# STMP3770 register map
Vendor: Freescale Semiconductor (NXP); Series: STMP37xx; File version: 1.0
CPU: other r0p0, little endian, no MPU, no FPU, 2 interrupt priority bits
Registers are 32-bit, read-write, reset 0x0 unless marked. A register's access mark holds for its fields unless they carry their own. Offsets are from the block's base; [hi:lo] are bit positions; <NAME> marks a mode.

## AUDIOOUT — 音频 DAC 输出(耳机/线路输出的音量、滤波与 DMA 控制)
Base 0x80048000
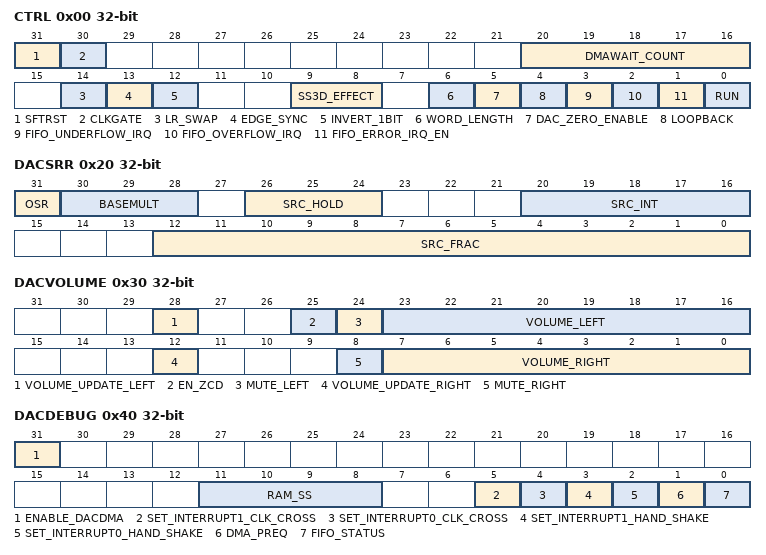
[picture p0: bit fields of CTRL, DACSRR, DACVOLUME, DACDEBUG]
0x00 CTRL — AUDIOOUT Control Register
  [31] SFTRST — Module Soft Reset. Set to 1 to force reset to portions of DIGFILT controlling AUDIOOUT, then gates clocks off. Clear to 0 for normal operation.
  [30] CLKGATE — Clock Gate Enable. When set to 1, gates off clocks to DIGFILT portions controlling only output audio functions. Clear to 0 for normal operation.
  [20:16] DMAWAIT_COUNT — DMA Request Delay Count. Specifies number of APBX clock cycles (0 to 31) to delay before each DMA request. Acts as a bandwidth throttle.
  [14] LR_SWAP — Left/Right Output Channel Swap Enable. When set, swaps left and right serial audio outputs from SDM to analog DAC.
  [13] EDGE_SYNC — Serial Output Clock Edge Sync Select. 0=Rising edge, 1=Falling edge for SDM synchronization.
  [12] INVERT_1BIT — Invert Serial Audio Output Enable. Inverts the 1-bit serial output of both channels to the sigma-delta modulator.
  [9:8] SS3D_EFFECT — Virtual 3D Effect Enable. Subtracts opposite channel content. 00=Off, 01=Low (3dB), 10=Medium (4.5dB), 11=High (6dB).
  [6] WORD_LENGTH — PCM Audio Bit Size Select. 0=32-bit PCM samples, 1=16-bit samples.
  [5] DAC_ZERO_ENABLE — Quiet Output Enable. Causes SDM to transmit alternating ones and zeros for pop-suppression. Reset by power-on reset only.
  [4] LOOPBACK — AUDIOIN-to-AUDIOOUT Loopback Enable. Routes AUDIOIN FIFO data to AUDIOOUT FIFO for test.
  [3] FIFO_UNDERFLOW_IRQ — FIFO Underflow Interrupt Status. Set by hardware on FIFO underflow. Clear by writing 1 to CLR register.
  [2] FIFO_OVERFLOW_IRQ — FIFO Overflow Interrupt Status. Set by hardware on FIFO overflow. Clear by writing 1 to CLR register.
  [1] FIFO_ERROR_IRQ_EN — FIFO Error Interrupt Enable. Enables interrupt when overflow or underflow status bits are set.
  [0] RUN — AUDIOOUT Enable. Set to 1 to start operation with DMA request. Clear to 0 stops conversion and sets CLKGATE.
0x10 STAT — AUDIOOUT Status Register
  [31] DAC_PRESENT — AUDIOOUT Functionality Present. Set to 1 if DAC is present. 0 means permanently disabled.
0x20 DACSRR — AUDIOOUT Sample Rate Register
  [31] OSR — Oversample Rate. Fixed at 6 MHz for STMP3770. 0x0=6 MHz, 0x1=12 MHz.
    0=OSR6; 1=OSR12
  [30:28] BASEMULT — Base Sample Rate Multiplier. 0x1=Single (48/44.1/32 kHz), 0x2=Double (96/88.2/64 kHz), 0x4=Quad (192/176.4/128 kHz).
    1=SINGLE_RATE; 2=DOUBLE_RATE; 4=QUAD_RATE
  [26:24] SRC_HOLD — Sample Rate Conversion Hold Factor. Used to generate half/quarter sample rates.
  [20:16] SRC_INT — Sample Rate Conversion Integer Factor. Integer portion of divide term for sample rate conversion.
  [12:0] SRC_FRAC — Sample Rate Conversion Fraction Factor. Fractional portion of divide term for sample rate conversion.
0x30 DACVOLUME — AUDIOOUT Volume Register
  [28] VOLUME_UPDATE_LEFT — Left Channel Volume Update Pending. Set by hardware when volume update pending on left channel zero-crossing.
  [25] EN_ZCD — Enable Zero-Cross Detect. When enabled, volume changes applied only at zero-crossing.
  [24] MUTE_LEFT — Mute Left Channel. 0=unmute, 1=mute. Applied immediately.
  [23:16] VOLUME_LEFT — Left Channel Volume Setting. -0.5dB (0xFE) to -100dB (0x37). Each increment = +0.5dB.
  [12] VOLUME_UPDATE_RIGHT — Right Channel Volume Update Pending. Set by hardware when volume update pending on right channel zero-crossing.
  [8] MUTE_RIGHT — Mute Right Channel. 0=Unmute, 1=Mute. Applied immediately.
  [7:0] VOLUME_RIGHT — Right Channel Volume Setting. -0.5dB (0xFE) to -100dB (0x37). Each increment = +0.5dB.
0x40 DACDEBUG — AUDIOOUT Debug Register
  [31] ENABLE_DACDMA — Digital Path Test Enable. Bypasses DAC analog for debug; transfers serial audio data via AUDIOIN DMA Channel 0.
  [11:8] RAM_SS — DIGFILT RAM Speed Select. Sense AMP timing control. Do not alter unless instructed by SigmaTel.
  [5] SET_INTERRUPT1_CLK_CROSS — Interrupt[1] Sync Status. State of sync flop chain for interrupt[1] signal. Test only.
  [4] SET_INTERRUPT0_CLK_CROSS — Interrupt[0] Sync Status. State of sync flop chain for interrupt[0] signal. Test only.
  [3] SET_INTERRUPT1_HAND_SHAKE — Interrupt[1] Status. State of APBX interface state machine interrupt[1] signal. Test only.
  [2] SET_INTERRUPT0_HAND_SHAKE — Interrupt[0] Status. State of APBX interface state machine interrupt[0] signal. Test only.
  [1] DMA_PREQ — DMA Request Status. Current state of AUDIOOUT DMA request signal. Can be polled for manual FIFO filling.
  [0] FIFO_STATUS — FIFO Status. Set when FIFO has empty entries, cleared when full.
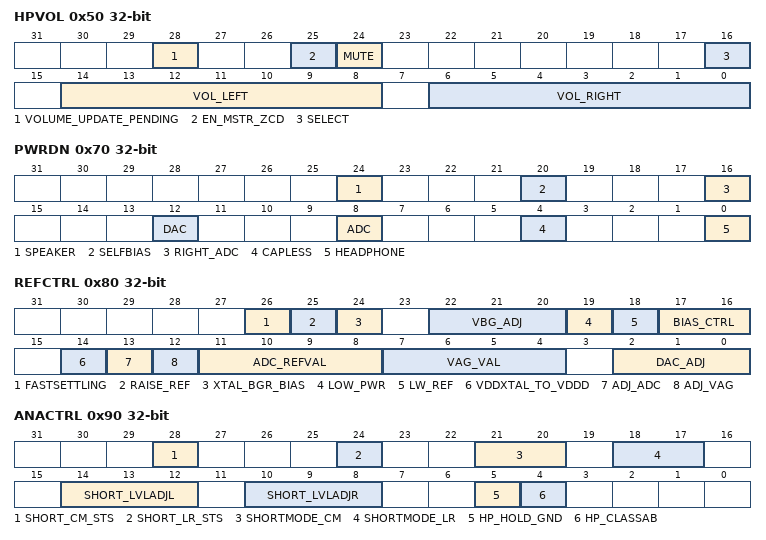
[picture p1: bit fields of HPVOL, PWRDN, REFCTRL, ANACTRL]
0x50 HPVOL — Headphone Volume and Select Control Register
  [28] VOLUME_UPDATE_PENDING — Volume Update Pending. Set when headphone volume update waiting on zero-crossing.
  [25] EN_MSTR_ZCD — Enable Zero-Cross Detect for Headphone Amplifier.
  [24] MUTE — Headphone Mute. Reset by power-on reset only.
  [16] SELECT — Input Signal Select. 0=DAC, 1=Line1. Reset by power-on reset only.
  [14:8] VOL_LEFT — Left Headphone Volume Control. 0.5dB steps. DAC mode: 0x00=+6dB to 0x7F=-57.5dB. Line1 mode: 0x00=+12dB to 0x7F=-51.5dB. Reset=0x0C (0dB). Power-on reset only.
  [6:0] VOL_RIGHT — Right Headphone Volume Control. 0.5dB steps. Same ranges as VOL_LEFT. Reset=0x0C (0dB). Power-on reset only.
0x70 PWRDN — Audio Power-Down Control Register
  [24] SPEAKER — 扬声器功放掉电，写1关闭以省电。
  [20] SELFBIAS — Currently does not control any logic; altering has no effect.
  [16] RIGHT_ADC — Right ADC Power Down. Powers down ADC right channel for mono operation. ADC function; reset by ADC SFTRST.
  [12] DAC — Power Down DAC Analog Circuitry. Reset by power-on reset only.
  [8] ADC — Power Down ADC and Input Mux Circuitry. ADC function; reset by ADC SFTRST.
  [4] CAPLESS — Power Down Headphone Common Amplifier for Capless Headphone. Reset by power-on reset only.
  [0] HEADPHONE — Master (Headphone) Power Down. Reset by power-on reset only.
0x80 REFCTRL — AUDIOOUT Reference Control Register
  [26] FASTSETTLING — Increases vag buffer output current by 2X to 20uA to improve startup settling time.
  [25] RAISE_REF — Must be low when VDDA < ~1.7V. When low, VAG and ADC ref voltages drop by factor 0.875.
  [24] XTAL_BGR_BIAS — Switch XTAL bias from self-bias to bandgap-based. Powers both DAC and ADC. Reset by power-on reset only.
  [22:20] VBG_ADJ — VBG adjustment. Affects ALL references. 000=Nominal, 001=+0.3%, 010=+0.6%, 011=+0.85%, 100=-0.3%, 101=-0.6%, 110=-0.9%, 111=-1.2%. Power-on reset only.
  [19] LOW_PWR — Lowers bandgap amplifier power (~100uA). Useful in USB suspend/standby. Power-on reset only.
  [18] LW_REF — This bit currently does not control any logic; altering its value has no effect.
  [17:16] BIAS_CTRL — Bias current control for all analog blocks. 00=Nominal, 01=-20%, 10=-10%, 11=+10%. Test/debug only. Power-on reset only.
  [14] VDDXTAL_TO_VDDD — Shorts XTAL oscillator supply to VDDD to reduce power. ADC function; reset by ADC SFTRST.
  [13] ADJ_ADC — ADC Reference Voltage Adjust. 0=1.5V/1.31V fixed ref. 1=controlled by ADC_REFVAL. Must be set when both ADC and DAC enabled.
  [12] ADJ_VAG — VAG select. 0=VDD/2 (resistor divider). 1=controlled by VAG_VAL. Controls both DAC and ADC. Power-on reset only.
  [11:8] ADC_REFVAL — ADC Reference Value. When ADJ_ADC=1: 0x7=1.60V, 0x0=1.425V, 25mV steps. Affected by RAISE_REF.
  [7:4] VAG_VAL — VAG Reference Value. When ADJ_VAG=1: 0x7=1.0V, 0x0=0.825V, 25mV steps. Affected by RAISE_REF. Power-on reset only.
  [2:0] DAC_ADJ — These bits have no effect.
0x90 ANACTRL — Miscellaneous Audio Controls Register
  [28] SHORT_CM_STS — Status of common mode amplifier short detection. 0=No short. Clear and rearm via SHORTMODE_CM sequence.
  [24] SHORT_LR_STS — Status of headphone amplifier short detection. 0=No short. Clear and rearm via SHORTMODE_LR sequence.
  [21:20] SHORTMODE_CM — Headphone Common Mode Amplifier Short Control. 00=Reset analog latch, 01=Latch short signal and HW power down.
  [18:17] SHORTMODE_LR — Headphone L/R Channel Short Control. 00=Reset latch no power-down, 01=Latch short signal with HW power-down.
  [14:12] SHORT_LVLADJL — Adjust left headphone current short detect trip point. 000=Nominal, +/-25/50/75/100%. Power-on reset only.
  [10:8] SHORT_LVLADJR — Adjust right headphone current short detect trip point. 000=Nominal, +/-25/50/75/100%. Power-on reset only.
  [5] HP_HOLD_GND — Hold Headphone Output to Ground. Used for power-up/power-down procedures. Power-on reset only.
  [4] HP_CLASSAB — Headphone amplifier mode. 0=ClassA (for power-up/down and short handling). 1=ClassAB (normal operation). Power-on reset only.
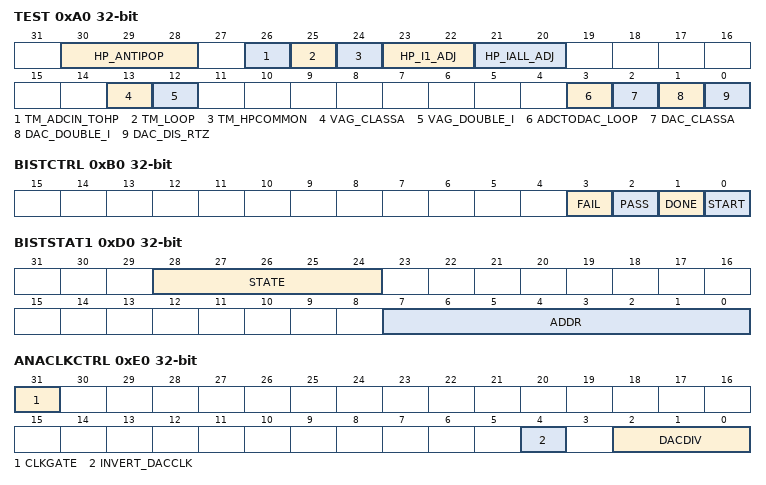
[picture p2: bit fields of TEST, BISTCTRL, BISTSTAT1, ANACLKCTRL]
0xA0 TEST — Miscellaneous Test Audio Controls Register
  [30:28] HP_ANTIPOP — Reserved.
  [26] TM_ADCIN_TOHP — Testmode: pipe ADC Mux Out to Headphone Output pins. ADC function; reset by ADC SFTRST.
  [25] TM_LOOP — 测试模式环回使能。
  [24] TM_HPCOMMON — Testmode: use headphone common VAG in ADC Mux for analog loopback DAC-HP-ADC.
  [23:22] HP_I1_ADJ — Adjust bias current in first stage of headphone amplifier. 00=Nominal, 01=-50%, 10=+100%, 11=+50%. Power-on reset only.
  [21:20] HP_IALL_ADJ — Adjust all bias current in headphone amplifier. 00=Nominal, 01=-50%, 10=+50%, 11=-40%. Power-on reset only.
  [13] VAG_CLASSA — Set to 1 to disable ClassAB mode in VAG Amp (+~200uA). Controls both DAC and ADC. Power-on reset only.
  [12] VAG_DOUBLE_I — Set to 1 to double ClassA current in VAG amplifier (+240uA). Power-on reset only.
  [3] ADCTODAC_LOOP — ADC到DAC环回测试使能。
  [2] DAC_CLASSA — Set to 1 to disable ClassAB mode in DAC (+~600uA).
  [1] DAC_DOUBLE_I — Set to 1 to double ClassA current in DAC amplifier (+360uA each DAC).
  [0] DAC_DIS_RTZ — Set to 1 to disable DAC RTZ mode. Test-only. Should remain cleared.
0xB0 BISTCTRL — BIST Control and Status Register
  [3] FAIL — BIST has failed.
  [2] PASS — BIST has passed.
  [1] DONE — BIST has completed.
  [0] START — Initiate BIST of internal memory.
0xC0 BISTSTAT0 — Hardware BIST Status 0 Register
  [23:0] DATA — Failing data at the failing address.
0xD0 BISTSTAT1 — Hardware AUDIOUT BIST Status 1 Register
  [28:24] STATE — Fail state of the BIST engine.
  [7:0] ADDR — Failing address from BIST.
0xE0 ANACLKCTRL — Analog Clock Control Register
  [31] CLKGATE — Analog clock Gate. Gate clocks for DAC converter and digital filter. Reset by power-on reset only.
  [4] INVERT_DACCLK — DAC Clock Invert. Invert DAC_CLK for sigma-delta converter and digital filters.
  [2:0] DACDIV — DAC Analog Clock Divider. Selects oversampling clock rate. 000=6MHz, 001=4MHz, 010/100=3MHz, 011/101=2MHz, 110=1.5MHz, 111=1MHz.
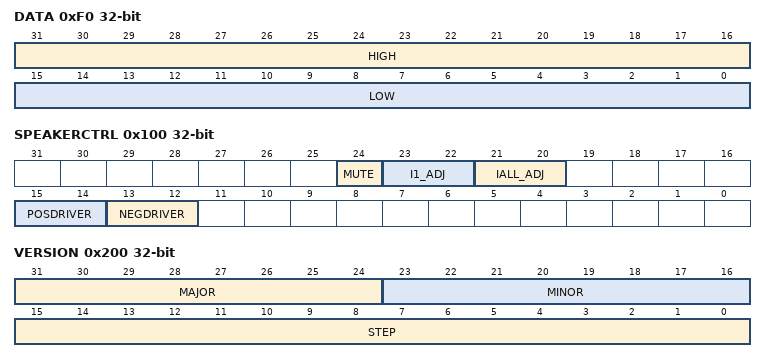
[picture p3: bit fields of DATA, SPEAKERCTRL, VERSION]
0xF0 DATA — AUDIOOUT Write Data Register
  [31:16] HIGH — Right Sample or Sample High Half-Word. For 16-bit mode: right channel. For 32-bit mode: MSB 16 bits.
  [15:0] LOW — Left Sample or Sample Low Half-Word. For 16-bit mode: left channel. For 32-bit mode: LSB 16 bits.
0x100 SPEAKERCTRL — AUDIOOUT Speaker Control Register
  [24] MUTE — 扬声器静音控制。
  [23:22] I1_ADJ — 扬声器段1电流调整。
  [21:20] IALL_ADJ — 扬声器总电流调整。
  [15:14] POSDRIVER — 扬声器正端驱动控制。
  [13:12] NEGDRIVER — 扬声器负端驱动控制。
0x200 VERSION ro — AUDIOOUT Version Register
  [31:24] MAJOR — Fixed read-only RTL version major field. Reset=0x01.
  [23:16] MINOR — Fixed read-only RTL version minor field. Reset=0x01.
  [15:0] STEP — Fixed read-only RTL version stepping field. Reset=0x0000.
